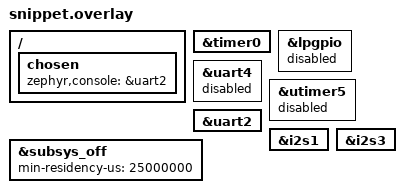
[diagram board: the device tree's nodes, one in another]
/* Copyright (C) 2025 Alif Semiconductor - All Rights Reserved.
 * Use, distribution and modification of this code is permitted under the
 * terms stated in the Alif Semiconductor Software License Agreement
 *
 * You should have received a copy of the Alif Semiconductor Software
 * License Agreement with this file. If not, please write to:
 * contact@alifsemi.com, or visit: https://alifsemi.com/license
 *
 */

&timer0 {
	status = "okay";
};

&lpgpio {
	status = "disabled";
};

&uart4 {
	status = "disabled";
};

&utimer5 {
	status = "disabled";
};

&uart2 {
	status = "okay";
};

&subsys_off {
	min-residency-us = <25000000>;
	status = "okay";
};

/*
 * I2S_1 => Speaker Output
 * I2S_3 => Mic Input
 */

i2s_tx: &i2s1 {
	status = "okay";
};

i2s_rx: &i2s3 {
	status = "okay";
};

/ {
	chosen {
		zephyr,console = &uart2;
	};
};
